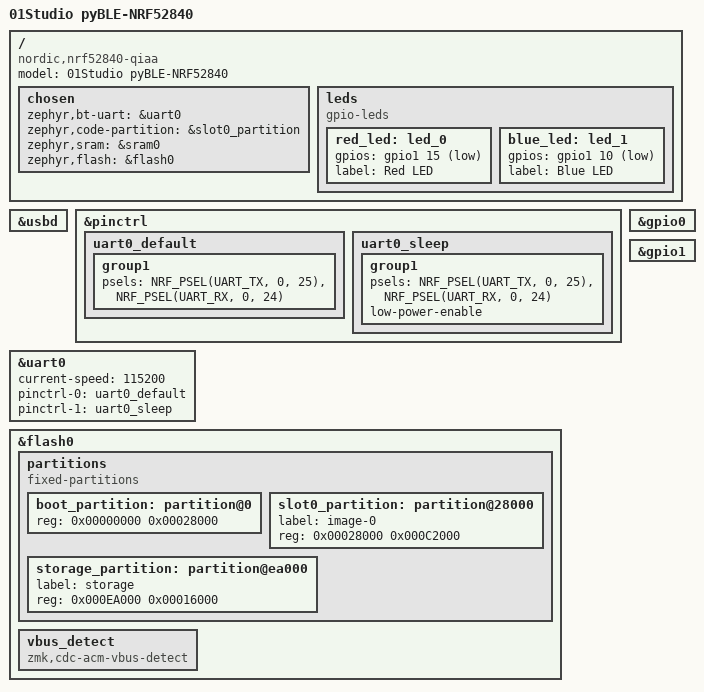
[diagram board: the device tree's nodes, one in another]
/dts-v1/;
#include <nordic/nrf52840_qiaa.dtsi>

/ {
    model = "01Studio pyBLE-NRF52840";
    compatible = "nordic,nrf52840-qiaa";

    chosen {
        zephyr,bt-uart = &uart0;
        zephyr,code-partition = &slot0_partition;
        zephyr,sram = &sram0;
        zephyr,flash = &flash0;
    };

    leds {
        compatible = "gpio-leds";
        red_led: led_0 {
            gpios = <&gpio1 15 GPIO_ACTIVE_LOW>;
            label = "Red LED";
        };
        blue_led: led_1 {
            gpios = <&gpio1 10 GPIO_ACTIVE_LOW>;
            label = "Blue LED";
        };
    };
};

zephyr_udc0: &usbd {
    status = "okay";
};

&pinctrl {
    uart0_default: uart0_default {
        group1 {
            psels = <NRF_PSEL(UART_TX, 0, 25)>,
                    <NRF_PSEL(UART_RX, 0, 24)>;
        };
    };

    uart0_sleep: uart0_sleep {
        group1 {
            psels = <NRF_PSEL(UART_TX, 0, 25)>,
                    <NRF_PSEL(UART_RX, 0, 24)>;
            low-power-enable;
        };
    };
};

&uart0 {
    status = "okay";
    current-speed = <115200>;
    pinctrl-0 = <&uart0_default>;
    pinctrl-1 = <&uart0_sleep>;
    pinctrl-names = "default", "sleep";
};

&gpio0 { status = "okay"; };
&gpio1 { status = "okay"; };

&flash0 {
    partitions {
        compatible = "fixed-partitions";
        #address-cells = <1>;
        #size-cells = <1>;

        boot_partition: partition@0 {
            reg = <0x00000000 0x00028000>;
        };

        slot0_partition: partition@28000 {
            label = "image-0";
            reg = <0x00028000 0x000C2000>; 
        };

        storage_partition: partition@ea000 {
            label = "storage";
            reg = <0x000EA000 0x00016000>;
        };
    };
    vbus_detect: vbus_detect {
        compatible = "zmk,cdc-acm-vbus-detect";
    };
};
